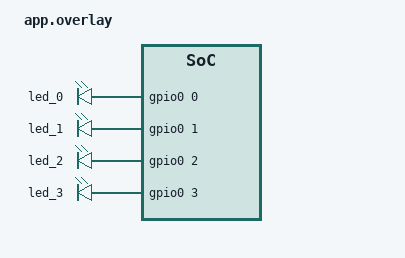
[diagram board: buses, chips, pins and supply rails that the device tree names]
/ {
    aliases {
        led0 = &led_0;
        led1 = &led_1;
        led2 = &led_2;
        led3 = &led_3;
          
    };

    leds {
        compatible = "gpio-leds";

        led_0: led_0 {
            gpios = <&gpio0 0 GPIO_ACTIVE_HIGH>;
        };
        led_1: led_1 {
            gpios = <&gpio0 1 GPIO_ACTIVE_HIGH>;
        };
        led_2: led_2 {
            gpios = <&gpio0 2 GPIO_ACTIVE_HIGH>;
        };
        led_3: led_3 {
            gpios = <&gpio0 3 GPIO_ACTIVE_HIGH>;
        };
    
    };
};
